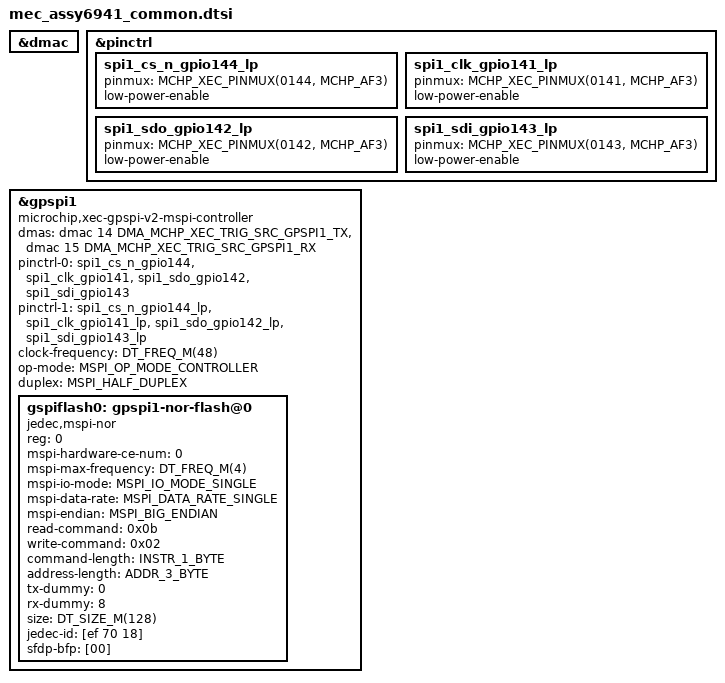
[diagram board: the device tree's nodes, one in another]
/*
 * Copyright (c) 2026 Microchip Technology Inc.
 *
 * SPDX-License-Identifier: Apache-2.0
 */

/* mec_assy6941 EVB with MEC1753 daughter card.
 * QMSPI controller 0 jumpered to SHD SPI pins on header J18
 * Install SPI dongle assy6791 dongle on header J18
 * Dongle has four W25Q128JV 3.3V flash JEDEC-ID = 0xef, 0x40, 0x18
 * J18 2x10 for SPI donlge Assembly 6971
 * GPIO055/SHD_nCS0 -> J18.4  1SPI_nCS0
 * GPIO002/SHD_nCS1 -> J18.10 1SPI_nCS1
 * GPIO056/SHD_CLK  -> J18.2  1SPI_CLK
 * GPIO223/SHD_IO0  -> J18.6  1SPI_MOSI
 * GPIO224/SHD_IO1  -> J18.7  1SPI_MISO
 * GPIO227/SHD_IO2  -> J18.8  1SPI_nWP
 * GPIO016/SHD_IO3  -> J18.9  1SPI_nHOLD
 *
 * SHD SPI jumpers
 * JP18 3x7 SHD_SPI pins
 * ---------------------
 *  2-3  select SHD_IO0
 *  5-6  select SHD_IO1
 *  8-9  select SHD_IO2
 * 11-12 select SHD_IO3
 * 14-15 select SHD_nCS0
 * 17-18 select SHD_CLK
 * 20-12 select SHD_nCS1
 *
 * GP-SPI controller 1 connected to socket U7 containing
 * Winbond 25Q128JVSM +3.3V flash JEDEC-ID = 0xef, 0x70, 0x18
 * U7-5 SPI1_MOSI
 * U7-2 SPI1_MISO
 * U7-6 SPI1_CLK
 * U7-1 SPI1_nCS
 *
 * Jumper block JP20 3x4
 * 2-3 ON choose SPI1_nCS
 * 5-6 ON choose SPI1_MIS0
 * 8-9 ON choose SPI1_CLK
 * 11-12 ON choose SPI1_MOSI
 *
 * Header J37 1x6
 * 1 = VTR1
 * 2 = SPI1_CLK
 * 3 = SPI1_MOSI
 * 4 = SPI1_MISO
 * 5 = SPI1_nCS
 * 6 = GND
 *
 * W25Q128JV(SM) 3.3V flash devices support commands:
 *   1-1-1 Page program 0x02
 *   1-1-4 Page program 0x32
 *   1-1-1 Read 0x03 <= 20 MHz, no dummy clocks
 *   1-1-1 Fast Read  0x0b plus 8 dummy clocks
 *   1-1-2 Fast Read Dual Output 0x3b plus 8 dummy clocks
 *   1-1-4 Fast Read Quad Output 0x6b plus 8 dummy clocks
 *   1-2-2 Fast Read Dual 0xbb plus mode byte
 *   1-4-4 Fast Read Quad 0xeb, plus mode byte
 *
 * W25Q128FW 1.8V flash JEDEC-ID = 0xef, 0x60, 0x18
 * Same opcodes as above
 *
 * Requires mspi-endian = "MSPI_BIG_ENDIAN";
 * because QSPI operates most-significant-bit-first and the MSPI flash driver
 * defaults to MSPI_LITTLE_ENDIAN if mspi-endian property is not present!
 */

#include <zephyr/dt-bindings/dma/mchp-xec-dmac.h>

/* The Zephyr MSPI driver Kconfig rules enable CONFIG_DMA
 * if CONFIG_MSPI_DMA is enabled. MCHP QMSPI based MSPI driver
 * uses the local-DMA channels built into the QMSPI controller.
 * We did not want to change MSPI Kconfig rules so we must enable
 * our central DMA controller even though it is not used by QMSPI MSPI.
 * The MSPI driver for the GPSPI controllers use central-DMA and require
 * the DMA driver (it has no local DMA).
 */
&dmac {
	status = "okay";
};

&pinctrl {
	spi1_cs_n_gpio144_lp: spi1_cs_n_gpio144_lp {
		pinmux = <MCHP_XEC_PINMUX(0144, MCHP_AF3)>;
		low-power-enable;
	};

	spi1_clk_gpio141_lp: spi1_clk_gpio141_lp {
		pinmux = <MCHP_XEC_PINMUX(0141, MCHP_AF3)>;
		low-power-enable;
	};

	spi1_sdo_gpio142_lp: spi1_sdo_gpio142_lp {
		pinmux = <MCHP_XEC_PINMUX(0142, MCHP_AF3)>;
		low-power-enable;
	};

	spi1_sdi_gpio143_lp: spi1_sdi_gpio143_lp {
		pinmux = <MCHP_XEC_PINMUX(0143, MCHP_AF3)>;
		low-power-enable;
	};
};

&gpspi1 {
	compatible = "microchip,xec-gpspi-v2-mspi-controller";
	status = "okay";

	dmas = <&dmac 14 DMA_MCHP_XEC_TRIG_SRC_GPSPI1_TX>,
	       <&dmac 15 DMA_MCHP_XEC_TRIG_SRC_GPSPI1_RX>;
	dma-names = "tx", "rx";

	pinctrl-0 = <&spi1_cs_n_gpio144 &spi1_clk_gpio141
		     &spi1_sdo_gpio142 &spi1_sdi_gpio143>;
	pinctrl-1 = <&spi1_cs_n_gpio144_lp &spi1_clk_gpio141_lp
		     &spi1_sdo_gpio142_lp &spi1_sdi_gpio143_lp>;
	pinctrl-names = "default", "sleep";

	clock-frequency = <DT_FREQ_M(48)>; /* Maximum frequency the controller can support */
	op-mode = "MSPI_OP_MODE_CONTROLLER";
	duplex = "MSPI_HALF_DUPLEX";

	gspiflash0: gpspi1-nor-flash@0 {
		compatible = "jedec,mspi-nor";
		reg = <0>;
		mspi-hardware-ce-num = <0>;
		mspi-max-frequency = <DT_FREQ_M(4)>;
		mspi-io-mode = "MSPI_IO_MODE_SINGLE";
		mspi-data-rate = "MSPI_DATA_RATE_SINGLE";
		mspi-endian = "MSPI_BIG_ENDIAN";
		read-command = <0x0b>;
		write-command = <0x02>;
		command-length = "INSTR_1_BYTE";
		address-length = "ADDR_3_BYTE";
		tx-dummy = <0>;
		rx-dummy = <8>;
		size = <DT_SIZE_M(128)>;
		jedec-id = [ef 70 18];
		sfdp-bfp = [00];
		status = "okay";
	};
};
